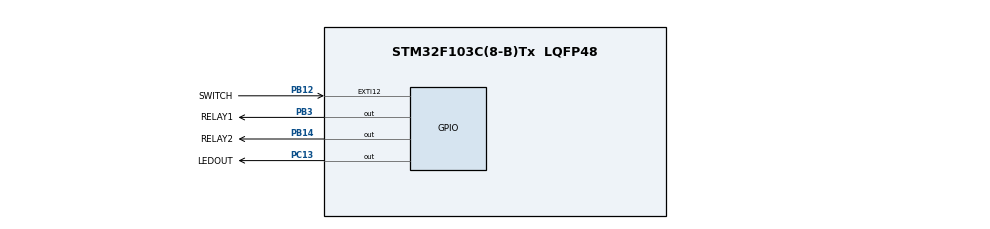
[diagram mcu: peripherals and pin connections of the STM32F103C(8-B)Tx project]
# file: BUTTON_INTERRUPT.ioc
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Mcu.Family=STM32F1
Mcu.Name=STM32F103C(8-B)Tx
Mcu.Package=LQFP48
NVIC.EXTI15_10_IRQn=true\:0\:0\:false\:false\:true\:true\:true\:true
NVIC.PriorityGroup=NVIC_PRIORITYGROUP_4
PA13.Mode=Serial_Wire
PA13.Signal=SYS_JTMS-SWDIO
PA14.Mode=Serial_Wire
PA14.Signal=SYS_JTCK-SWCLK
PB12.GPIO_Label=SWITCH
PB12.GPIO_ModeDefaultEXTI=GPIO_MODE_IT_RISING_FALLING
PB12.Signal=GPXTI12
PB14.GPIO_Label=RELAY2
PB14.Signal=GPIO_Output
PB3.GPIO_Label=RELAY1
PB3.Signal=GPIO_Output
PC13-TAMPER-RTC.GPIO_Label=LEDOUT
PC13-TAMPER-RTC.Signal=GPIO_Output
ProjectManager.HeapSize=0x200
ProjectManager.StackSize=0x400
ProjectManager.TargetToolchain=MDK-ARM V5.27
RCC.APB1Freq_Value=8000000
RCC.APB2Freq_Value=8000000
board=custom

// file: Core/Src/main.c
/* USER CODE BEGIN Header */
/**
  ******************************************************************************
  * @file           : main.c
  * @brief          : Main program body
  ******************************************************************************
  * @attention
  *
  * Copyright (c) 2026 STMicroelectronics.
  * All rights reserved.
  *
  * This software is licensed under terms that can be found in the LICENSE file
  * in the root directory of this software component.
  * If no LICENSE file comes with this software, it is provided AS-IS.
  *
  ******************************************************************************
  */
/* USER CODE END Header */
#include "main.h"

/* USER CODE BEGIN PV */
uint32_t lastDebounceTime = 0,DELAY = 0;  /* stores last interrupt time */

uint8_t  relayState = 1;        /* current relay state */
uint8_t  btnEdgeDetected = 0;     /* flag: edge was seen */

uint32_t btnEdgeTime     = 0;     /* when edge was seen  */

/* USER CODE END PV */

void SystemClock_Config(void);
static void MX_GPIO_Init(void);

int main(void)
{

  /* MCU Configuration--------------------------------------------------------*/

  /* Reset of all peripherals, Initializes the Flash interface and the Systick. */
  HAL_Init();

  /* Configure the system clock */
  SystemClock_Config();

  /* Initialize all configured peripherals */
  MX_GPIO_Init();

  /* Infinite loop */
  /* USER CODE BEGIN WHILE */
  while (1)
  {
		//after button press
		//but after 50ms still press. then relay1-2 on and off
		if(btnEdgeDetected == 1)
		{
			if((HAL_GetTick() - btnEdgeTime) >= 50)
			{
				btnEdgeDetected = 0;
				if(HAL_GPIO_ReadPin(SWITCH_GPIO_Port, SWITCH_Pin) == GPIO_PIN_RESET)

				{

					HAL_GPIO_WritePin(RELAY1_GPIO_Port, RELAY1_Pin, GPIO_PIN_SET);
					HAL_GPIO_WritePin(RELAY2_GPIO_Port, RELAY2_Pin, GPIO_PIN_SET);
				}
				else
				{
					HAL_GPIO_WritePin(RELAY1_GPIO_Port, RELAY1_Pin, GPIO_PIN_RESET);
					HAL_GPIO_WritePin(RELAY2_GPIO_Port, RELAY2_Pin, GPIO_PIN_RESET);
				}
			}
		}

		//use for every 500ms toggle LEDOUT pin
		if((HAL_GetTick() - DELAY) >= 500)
		{
			DELAY = HAL_GetTick();
			HAL_GPIO_TogglePin(GPIOC, GPIO_PIN_13);
		}
  }
}

void SystemClock_Config(void)
{
  RCC_OscInitTypeDef RCC_OscInitStruct = {0};
  RCC_ClkInitTypeDef RCC_ClkInitStruct = {0};

  /** Initializes the RCC Oscillators according to the specified parameters
  * in the RCC_OscInitTypeDef structure.
  */
  RCC_OscInitStruct.OscillatorType = RCC_OSCILLATORTYPE_HSI;
  RCC_OscInitStruct.HSIState = RCC_HSI_ON;
  RCC_OscInitStruct.HSICalibrationValue = RCC_HSICALIBRATION_DEFAULT;
  RCC_OscInitStruct.PLL.PLLState = RCC_PLL_NONE;
  if (HAL_RCC_OscConfig(&RCC_OscInitStruct) != HAL_OK)
  {
    Error_Handler();
  }

  /** Initializes the CPU, AHB and APB buses clocks
  */
  RCC_ClkInitStruct.ClockType = RCC_CLOCKTYPE_HCLK|RCC_CLOCKTYPE_SYSCLK
                              |RCC_CLOCKTYPE_PCLK1|RCC_CLOCKTYPE_PCLK2;
  RCC_ClkInitStruct.SYSCLKSource = RCC_SYSCLKSOURCE_HSI;
  RCC_ClkInitStruct.AHBCLKDivider = RCC_SYSCLK_DIV1;
  RCC_ClkInitStruct.APB1CLKDivider = RCC_HCLK_DIV1;
  RCC_ClkInitStruct.APB2CLKDivider = RCC_HCLK_DIV1;

  if (HAL_RCC_ClockConfig(&RCC_ClkInitStruct, FLASH_LATENCY_0) != HAL_OK)
  {
    Error_Handler();
  }
}

static void MX_GPIO_Init(void)
{
  GPIO_InitTypeDef GPIO_InitStruct = {0};

  /* GPIO Ports Clock Enable */
  __HAL_RCC_GPIOC_CLK_ENABLE();
  __HAL_RCC_GPIOB_CLK_ENABLE();
  __HAL_RCC_GPIOA_CLK_ENABLE();

  /*Configure GPIO pin Output Level */
  HAL_GPIO_WritePin(LEDOUT_GPIO_Port, LEDOUT_Pin, GPIO_PIN_RESET);

  /*Configure GPIO pin Output Level */
  HAL_GPIO_WritePin(GPIOB, RELAY2_Pin|RELAY1_Pin, GPIO_PIN_RESET);

  /*Configure GPIO pin : LEDOUT_Pin */
  GPIO_InitStruct.Pin = LEDOUT_Pin;
  GPIO_InitStruct.Mode = GPIO_MODE_OUTPUT_PP;
  GPIO_InitStruct.Pull = GPIO_NOPULL;
  GPIO_InitStruct.Speed = GPIO_SPEED_FREQ_LOW;
  HAL_GPIO_Init(LEDOUT_GPIO_Port, &GPIO_InitStruct);

  /*Configure GPIO pin : SWITCH_Pin */
  GPIO_InitStruct.Pin = SWITCH_Pin;
  GPIO_InitStruct.Mode = GPIO_MODE_IT_RISING_FALLING;
  GPIO_InitStruct.Pull = GPIO_NOPULL;
  HAL_GPIO_Init(SWITCH_GPIO_Port, &GPIO_InitStruct);

  /*Configure GPIO pins : RELAY2_Pin RELAY1_Pin */
  GPIO_InitStruct.Pin = RELAY2_Pin|RELAY1_Pin;
  GPIO_InitStruct.Mode = GPIO_MODE_OUTPUT_PP;
  GPIO_InitStruct.Pull = GPIO_NOPULL;
  GPIO_InitStruct.Speed = GPIO_SPEED_FREQ_LOW;
  HAL_GPIO_Init(GPIOB, &GPIO_InitStruct);

  /* EXTI interrupt init*/
  HAL_NVIC_SetPriority(EXTI15_10_IRQn, 0, 0);
  HAL_NVIC_EnableIRQ(EXTI15_10_IRQn);

}

/* USER CODE BEGIN 4 */
void HAL_GPIO_EXTI_Callback(uint16_t GPIO_Pin)
{
  if(GPIO_Pin == SWITCH_Pin)
  {
    btnEdgeDetected = 1;              /* mark edge seen */

    btnEdgeTime     = HAL_GetTick(); /* record the time */

    /* DO NOTHING ELSE — no relay control here */
  }
}

//void HAL_GPIO_EXTI_Callback(uint16_t GPIO_Pin)

//{

//  if(GPIO_Pin == SWITCH_Pin)  /* confirm it is PB12 */

//  {

//    /* Debounce � ignore if <50ms since last trigger */

//    if((HAL_GetTick() - lastDebounceTime) > 50)

//    {

//      lastDebounceTime = HAL_GetTick();  /* update time */

//

//      /* Read actual button state after debounce */

//      if(HAL_GPIO_ReadPin(SWITCH_GPIO_Port, SWITCH_Pin) == GPIO_PIN_SET)

//      {

//        /* Button PRESSED (HIGH) � relays OFF */

//        HAL_GPIO_WritePin(RELAY2_GPIO_Port, RELAY2_Pin, GPIO_PIN_RESET);

//        HAL_GPIO_WritePin(RELAY1_GPIO_Port, RELAY1_Pin, GPIO_PIN_RESET);

//      }

//      else

//      {

//        /* Button RELEASED (LOW) � relays ON */

//        HAL_GPIO_WritePin(RELAY2_GPIO_Port, RELAY2_Pin, GPIO_PIN_SET);

//        HAL_GPIO_WritePin(RELAY1_GPIO_Port, RELAY1_Pin, GPIO_PIN_SET);

//      }

//    }

//  }

//}

/* USER CODE END 4 */

void Error_Handler(void)
{
  __disable_irq();
  while (1)
  {
  }
}
